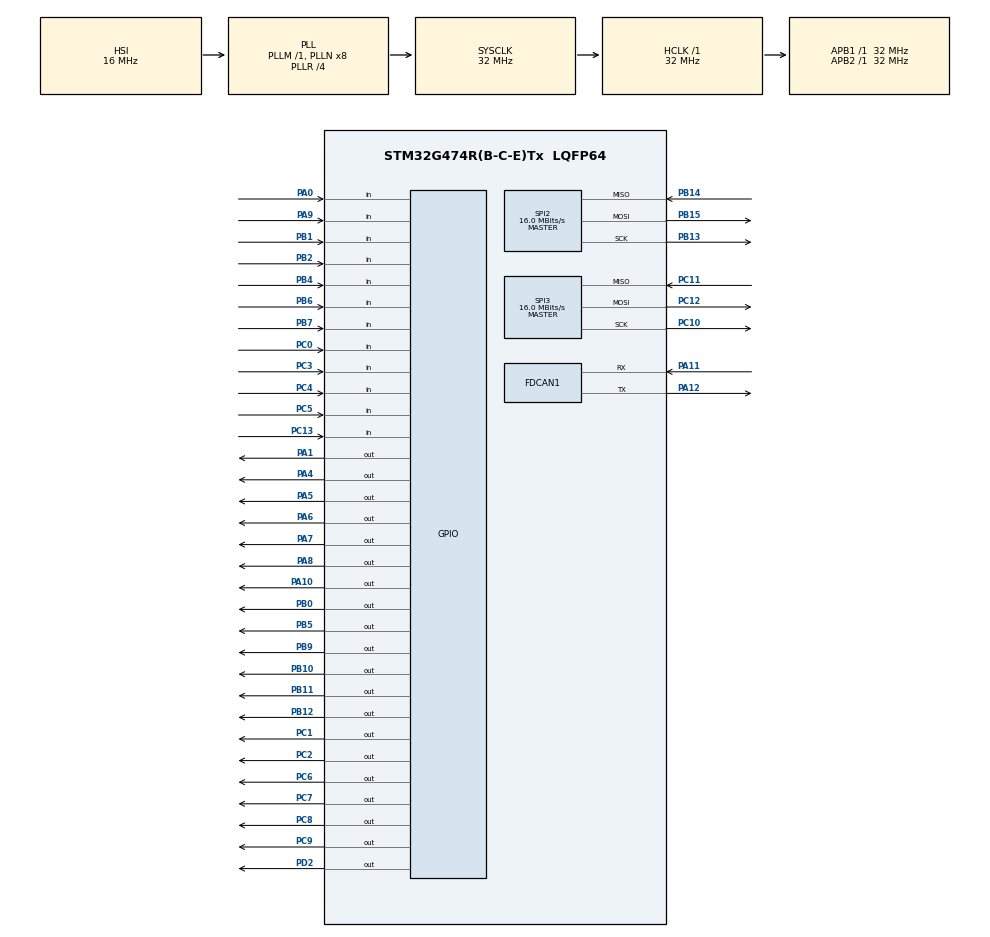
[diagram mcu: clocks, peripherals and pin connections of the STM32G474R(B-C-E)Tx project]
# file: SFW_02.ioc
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FDCAN1.CalculateBaudRateNominal=666666
FDCAN1.CalculateTimeBitNominal=1500
FDCAN1.CalculateTimeQuantumNominal=500.0
Mcu.Family=STM32G4
Mcu.Name=STM32G474R(B-C-E)Tx
Mcu.Package=LQFP64
NVIC.PriorityGroup=NVIC_PRIORITYGROUP_4
NVIC.TIM2_IRQn=true\:0\:0\:false\:false\:true\:true\:true\:true
PA0.Signal=GPIO_Input
PA1.Signal=GPIO_Output
PA10.Signal=GPIO_Output
PA11.Mode=FDCAN_Activate
PA11.Signal=FDCAN1_RX
PA12.Mode=FDCAN_Activate
PA12.Signal=FDCAN1_TX
PA13.Signal=SYS_JTMS-SWDIO
PA14.Signal=SYS_JTCK-SWCLK
PA15.Signal=SYS_JTDI
PA2.Signal=LPUART1_TX
PA3.Signal=LPUART1_RX
PA4.Signal=GPIO_Output
PA5.Signal=GPIO_Output
PA6.Signal=GPIO_Output
PA7.Signal=GPIO_Output
PA8.Signal=GPIO_Output
PA9.Signal=GPIO_Input
PB0.Signal=GPIO_Output
PB1.Signal=GPIO_Input
PB10.Signal=GPIO_Output
PB11.Signal=GPIO_Output
PB12.Signal=GPIO_Output
PB13.Mode=Full_Duplex_Master
PB13.Signal=SPI2_SCK
PB14.Mode=Full_Duplex_Master
PB14.Signal=SPI2_MISO
PB15.Mode=Full_Duplex_Master
PB15.Signal=SPI2_MOSI
PB2.Signal=GPIO_Input
PB3.Signal=SYS_JTDO-SWO
PB4.Signal=GPIO_Input
PB5.Signal=GPIO_Output
PB6.Signal=GPIO_Input
PB7.Signal=GPIO_Input
PB9.Signal=GPIO_Output
PC0.Signal=GPIO_Input
PC1.Signal=GPIO_Output
PC10.Mode=Full_Duplex_Master
PC10.Signal=SPI3_SCK
PC11.Mode=Full_Duplex_Master
PC11.Signal=SPI3_MISO
PC12.Mode=Full_Duplex_Master
PC12.Signal=SPI3_MOSI
PC13.Signal=GPIO_Input
PC14-OSC32_IN.Mode=LSE-External-Oscillator
PC14-OSC32_IN.Signal=RCC_OSC32_IN
PC15-OSC32_OUT.Mode=LSE-External-Oscillator
PC15-OSC32_OUT.Signal=RCC_OSC32_OUT
PC2.Signal=GPIO_Output
PC3.Signal=GPIO_Input
PC4.Signal=GPIO_Input
PC5.Signal=GPIO_Input
PC6.Signal=GPIO_Output
PC7.Signal=GPIO_Output
PC8.Signal=GPIO_Output
PC9.Signal=GPIO_Output
PD2.Signal=GPIO_Output
PF0-OSC_IN.Mode=HSE-External-Oscillator
PF0-OSC_IN.Signal=RCC_OSC_IN
PF1-OSC_OUT.Mode=HSE-External-Oscillator
PF1-OSC_OUT.Signal=RCC_OSC_OUT
ProjectManager.HeapSize=0x200
ProjectManager.StackSize=0x400
ProjectManager.TargetToolchain=STM32CubeIDE
RCC.ADC12Freq_Value=32000000
RCC.ADC345Freq_Value=32000000
RCC.AHBFreq_Value=32000000
RCC.APB1Freq_Value=32000000
RCC.APB1TimFreq_Value=32000000
RCC.APB2Freq_Value=32000000
RCC.APB2TimFreq_Value=32000000
RCC.CortexFreq_Value=32000000
RCC.EXTERNAL_CLOCK_VALUE=12288000
RCC.HCLKFreq_Value=32000000
RCC.HSE_VALUE=24000000
RCC.HSI48_VALUE=48000000
RCC.HSI_VALUE=16000000
RCC.PLLR=RCC_PLLR_DIV4
RCC.SYSCLKFreq_VALUE=32000000
RCC.SYSCLKSource=RCC_SYSCLKSOURCE_PLLCLK
RCC.USBFreq_Value=64000000
RCC.VCOOutputFreq_Value=128000000
SPI2.BaudRatePrescaler=SPI_BAUDRATEPRESCALER_2
SPI2.CalculateBaudRate=16.0 MBits/s
SPI2.Direction=SPI_DIRECTION_2LINES
SPI2.Mode=SPI_MODE_MASTER
SPI2.VirtualType=VM_MASTER
SPI3.BaudRatePrescaler=SPI_BAUDRATEPRESCALER_2
SPI3.CalculateBaudRate=16.0 MBits/s
SPI3.Direction=SPI_DIRECTION_2LINES
SPI3.Mode=SPI_MODE_MASTER
SPI3.VirtualType=VM_MASTER
TIM2.Channel-PWM\ Generation1\ No\ Output=TIM_CHANNEL_1
TIM2.PeriodNoDither=999
TIM2.Prescaler=320
VP_SYS_VS_DBSignals.Mode=DisableDeadBatterySignals
VP_TIM2_VS_ClockSourceINT.Mode=Internal
VP_TIM2_VS_no_output1.Mode=PWM Generation1 No Output
VREF+.Mode=InternalMode
VREF+.Signal=VREFBUF_OUT
board=custom

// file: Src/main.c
/* USER CODE BEGIN Header */
/**
  ******************************************************************************
  * @file           : main.c
  * @brief          : Main program body
  ******************************************************************************
  * @attention
  *
  * Copyright (c) 2026 STMicroelectronics.
  * All rights reserved.
  *
  * This software is licensed under terms that can be found in the LICENSE file
  * in the root directory of this software component.
  * If no LICENSE file comes with this software, it is provided AS-IS.
  *
  ******************************************************************************
  */
/* USER CODE END Header */
#include "main.h"

/* USER CODE BEGIN Includes */
#include "stm32g4xx_hal.h"
#include "vnf1248.h"
/* USER CODE END Includes */

FDCAN_HandleTypeDef hfdcan1;

SPI_HandleTypeDef hspi2;
SPI_HandleTypeDef hspi3;

TIM_HandleTypeDef htim2;

/* USER CODE BEGIN PV */
uint8_t SPI2_TxBuf[4];
uint8_t SPI2_RxBuf[4];
uint8_t NVMread[3];

uint32_t k=0;
uint8_t NVMerr=0;
uint32_t cfg_word = 0;
int8_t OutputState=0;
/* USER CODE END PV */

void SystemClock_Config(void);
static void MX_GPIO_Init(void);
static void MX_FDCAN1_Init(void);
static void MX_SPI2_Init(void);
static void MX_SPI3_Init(void);
static void MX_TIM2_Init(void);

int main(void)
{

  /* MCU Configuration--------------------------------------------------------*/

  /* Reset of all peripherals, Initializes the Flash interface and the Systick. */
  HAL_Init();

  /* Configure the system clock */
  SystemClock_Config();

  /* Initialize all configured peripherals */
  MX_GPIO_Init();
  MX_FDCAN1_Init();
  MX_SPI2_Init();
  MX_SPI3_Init();
  MX_TIM2_Init();
//  HAL_TIM_Base_Start_IT(&htim2);
  /* USER CODE BEGIN 2 */

  //Initialize_vnf(&hspi2, GPIOC, GPIO_PIN_1);
  Initialize_vnf(&hspi2, GPIOC, GPIO_PIN_2);  // ch. B

  //NVMerr = RW_NVM_vnf(&hspi2, GPIOC, GPIO_PIN_2, 1);  // read NVM
  //RW_NVM_vnf(&hspi2, GPIOC, GPIO_PIN_2, 0);  // write NVM

  HAL_TIM_Base_Start_IT(&htim2);  // the interrupts is used to service VNF WD

  /* USER CODE END 2 */

  /* Infinite loop */
  /* USER CODE BEGIN WHILE */
  while (1)
  {
	  HAL_GPIO_TogglePin(GPIOB, GPIO_PIN_11);

	  if(HAL_GPIO_ReadPin(GPIOC, GPIO_PIN_3)==GPIO_PIN_SET)	// poll user button ; =0 when pressed
	  {
      HAL_GPIO_WritePin(GPIOB, GPIO_PIN_9, GPIO_PIN_RESET);	// disable 5V supply

	  }
	  else // button pressed
	  {

      // Read CR1
      SPI2_TxBuf[0] = 0b01000000|CR1_ADDR; // 0b01 = read command
      SPI2_TxBuf[1] = 0b00000000;
      SPI2_TxBuf[2] = 0b00000000;
      SPI2_TxBuf[3] = 0b00000000;
      VNF_TransmitReceive(&hspi2, GPIOC, GPIO_PIN_2, SPI2_TxBuf, SPI2_RxBuf);

      // CURRENT SENSE SELF-TEST
      // Read CR1
      SPI2_TxBuf[0] = 0b01000000|CR1_ADDR; // 0b01 = read command
      SPI2_TxBuf[1] = 0b00000000;
      SPI2_TxBuf[2] = 0b00000000;
      SPI2_TxBuf[3] = 0b00000000;
      VNF_TransmitReceive(&hspi2, GPIOC, GPIO_PIN_2, SPI2_TxBuf, SPI2_RxBuf);

      // Flip relevant bits and write CR1
      SPI2_TxBuf[0] = CR1_ADDR; // 0b00 = write command
      SPI2_TxBuf[1] = SPI2_RxBuf[1];
      SPI2_TxBuf[2] = SPI2_RxBuf[2]|0b10; // S_T_START bit = 1
      SPI2_TxBuf[3] = (SPI2_RxBuf[3]&0x1F)|0x20; // self-test current sense
      VNF_TransmitReceive(&hspi2, GPIOC, GPIO_PIN_2, SPI2_TxBuf, SPI2_RxBuf);

      // Read SR7
      SPI2_TxBuf[0] = 0b01000000|SR7_ADDR; // 0b01 = read command
      SPI2_TxBuf[1] = 0b00000000;
      SPI2_TxBuf[2] = 0b00000000;
      SPI2_TxBuf[3] = 0b00000000;
      VNF_TransmitReceive(&hspi2, GPIOC, GPIO_PIN_2, SPI2_TxBuf, SPI2_RxBuf);

      /*
      // FET STUCK ON SELF-TEST
      // Read CR1
      SPI2_TxBuf[0] = 0b01000000|CR1_ADDR; // 0b01 = read command
      SPI2_TxBuf[1] = 0b00000000;
      SPI2_TxBuf[2] = 0b00000000;
      SPI2_TxBuf[3] = 0b00000000;
      VNF_TransmitReceive(&hspi2, GPIOC, GPIO_PIN_2, SPI2_TxBuf, SPI2_RxBuf);

      // Flip relevant bits and write CR1
      SPI2_TxBuf[0] = CR1_ADDR; // 0b00 = write command
      SPI2_TxBuf[1] = SPI2_RxBuf[1];
      SPI2_TxBuf[2] = SPI2_RxBuf[2]|0b10; // S_T_START bit = 1
      SPI2_TxBuf[3] = (SPI2_RxBuf[3]&0x1F)|0x80; // self-test fet stuck-on
      VNF_TransmitReceive(&hspi2, GPIOC, GPIO_PIN_2, SPI2_TxBuf, SPI2_RxBuf);

      // Read SR6
      SPI2_TxBuf[0] = 0b01000000|SR6_ADDR; // 0b01 = read command
      SPI2_TxBuf[1] = 0b00000000;
      SPI2_TxBuf[2] = 0b00000000;
      SPI2_TxBuf[3] = 0b00000000;
      VNF_TransmitReceive(&hspi2, GPIOC, GPIO_PIN_2, SPI2_TxBuf, SPI2_RxBuf);
      */

      // PRE-CHARGE, TURN ON, THEN RUN VDS SELF-CHECK
      if(OutputState==0)
      {
        OutputState = 1; // using 1 for CCM
        //HAL_GPIO_WritePin(GPIOB, GPIO_PIN_10, GPIO_PIN_SET);

        // use pre-charge current trip threshold
        SPI2_TxBuf[0] = CR2_ADDR;
        SPI2_TxBuf[1] = (CR2_PRCHG&0x00FF0000)>>16;
		    SPI2_TxBuf[2] = (CR2_PRCHG&0x0000FF00)>>8;
		    SPI2_TxBuf[3] = (CR2_PRCHG&0x000000FF);
		    VNF_TransmitReceive(&hspi2, GPIOC, GPIO_PIN_2, SPI2_TxBuf, SPI2_RxBuf);

        SPI2_TxBuf[0] = CR1_ADDR; //0x008400
        SPI2_TxBuf[1] = 0x04; // --> trigger CCM ON
        SPI2_TxBuf[2] = 0x84;
        SPI2_TxBuf[3] = 0x00;
        VNF_TransmitReceive(&hspi2, GPIOC, GPIO_PIN_2, SPI2_TxBuf, SPI2_RxBuf);

        while(OutputState == 1)
        {
          // read SR1
          SPI2_TxBuf[0] = 0b01000000|SR1_ADDR; // 0b01 = read command
          SPI2_TxBuf[1] = 0b00000000;
          SPI2_TxBuf[2] = 0b00000000;
          SPI2_TxBuf[3] = 0b00000000;
          VNF_TransmitReceive(&hspi2, GPIOC, GPIO_PIN_2, SPI2_TxBuf, SPI2_RxBuf);

          switch((SPI2_RxBuf[1]&0xC0)>>6)
          {
            case 0b10:
              OutputState=2;
              break;

            case 0b11:
              OutputState=-1;
              break;

            case 0b00:
              OutputState=-2;
              break;

            default:
              break;
          }
        }

        if (OutputState == 2)
        {
          // revert to regular current trip threshold
          SPI2_TxBuf[0] = CR2_ADDR;
          SPI2_TxBuf[1] = (CR2_CONFIG&0x00FF0000)>>16;
          SPI2_TxBuf[2] = (CR2_CONFIG&0x0000FF00)>>8;
          SPI2_TxBuf[3] = (CR2_CONFIG&0x000000FF);
          VNF_TransmitReceive(&hspi2, GPIOC, GPIO_PIN_2, SPI2_TxBuf, SPI2_RxBuf);

          // turn FET ON
          SPI2_TxBuf[0] = CR1_ADDR; //0x008400
          SPI2_TxBuf[1] = 0x00;
          SPI2_TxBuf[2] = 0x84;
          SPI2_TxBuf[3] = 0x11; //--> turn on main FET
          VNF_TransmitReceive(&hspi2, GPIOC, GPIO_PIN_2, SPI2_TxBuf, SPI2_RxBuf);
          //HAL_GPIO_WritePin(GPIOB, GPIO_PIN_10, GPIO_PIN_RESET);

          // might need a delay here (to let motor current stabilize)
          // Run Vds self-check
          SPI2_TxBuf[0] = 0b01000000|CR1_ADDR; // 0b01 = read command
          SPI2_TxBuf[1] = 0b00000000;
          SPI2_TxBuf[2] = 0b00000000;
          SPI2_TxBuf[3] = 0b00000000;
          VNF_TransmitReceive(&hspi2, GPIOC, GPIO_PIN_2, SPI2_TxBuf, SPI2_RxBuf);

          // Flip relevant bits and write CR1
          SPI2_TxBuf[0] = CR1_ADDR; // 0b00 = write command
          SPI2_TxBuf[1] = SPI2_RxBuf[1];
          SPI2_TxBuf[2] = SPI2_RxBuf[2]|0b10; // S_T_START bit = 1
          SPI2_TxBuf[3] = (SPI2_RxBuf[3]&0x1F)|0x40; // self-test fet stuck-on
          VNF_TransmitReceive(&hspi2, GPIOC, GPIO_PIN_2, SPI2_TxBuf, SPI2_RxBuf);

          // Read SR5
          SPI2_TxBuf[0] = 0b01000000|SR5_ADDR; // 0b01 = read command
          SPI2_TxBuf[1] = 0b00000000;
          SPI2_TxBuf[2] = 0b00000000;
          SPI2_TxBuf[3] = 0b00000000;
          VNF_TransmitReceive(&hspi2, GPIOC, GPIO_PIN_2, SPI2_TxBuf, SPI2_RxBuf);
        }

      }

      // Read CR1
      SPI2_TxBuf[0] = 0b01000000|CR1_ADDR; // 0b01 = read command
      SPI2_TxBuf[1] = 0b00000000;
      SPI2_TxBuf[2] = 0b00000000;
      SPI2_TxBuf[3] = 0b00000000;
      VNF_TransmitReceive(&hspi2, GPIOC, GPIO_PIN_2, SPI2_TxBuf, SPI2_RxBuf);

      HAL_GPIO_WritePin(GPIOB, GPIO_PIN_9, GPIO_PIN_SET);	// enable 5V supply
	  }
  }
  /* USER CODE END 3 */
}

void HAL_TIM_PeriodElapsedCallback(TIM_HandleTypeDef* htim)
{
    PetWD_vnf(&hspi2, GPIOC, GPIO_PIN_2); // Ch. B
}

void SystemClock_Config(void)
{
  RCC_OscInitTypeDef RCC_OscInitStruct = {0};
  RCC_ClkInitTypeDef RCC_ClkInitStruct = {0};

  /** Configure the main internal regulator output voltage
  */
  HAL_PWREx_ControlVoltageScaling(PWR_REGULATOR_VOLTAGE_SCALE1);

  /** Initializes the RCC Oscillators according to the specified parameters
  * in the RCC_OscInitTypeDef structure.
  */
  RCC_OscInitStruct.OscillatorType = RCC_OSCILLATORTYPE_HSI;
  RCC_OscInitStruct.HSIState = RCC_HSI_ON;
  RCC_OscInitStruct.HSICalibrationValue = RCC_HSICALIBRATION_DEFAULT;
  RCC_OscInitStruct.PLL.PLLState = RCC_PLL_ON;
  RCC_OscInitStruct.PLL.PLLSource = RCC_PLLSOURCE_HSI;
  RCC_OscInitStruct.PLL.PLLM = RCC_PLLM_DIV1;
  RCC_OscInitStruct.PLL.PLLN = 8;
  RCC_OscInitStruct.PLL.PLLP = RCC_PLLP_DIV2;
  RCC_OscInitStruct.PLL.PLLQ = RCC_PLLQ_DIV2;
  RCC_OscInitStruct.PLL.PLLR = RCC_PLLR_DIV4;
  if (HAL_RCC_OscConfig(&RCC_OscInitStruct) != HAL_OK)
  {
    Error_Handler();
  }

  /** Initializes the CPU, AHB and APB buses clocks
  */
  RCC_ClkInitStruct.ClockType = RCC_CLOCKTYPE_HCLK|RCC_CLOCKTYPE_SYSCLK
                              |RCC_CLOCKTYPE_PCLK1|RCC_CLOCKTYPE_PCLK2;
  RCC_ClkInitStruct.SYSCLKSource = RCC_SYSCLKSOURCE_PLLCLK;
  RCC_ClkInitStruct.AHBCLKDivider = RCC_SYSCLK_DIV1;
  RCC_ClkInitStruct.APB1CLKDivider = RCC_HCLK_DIV1;
  RCC_ClkInitStruct.APB2CLKDivider = RCC_HCLK_DIV1;

  if (HAL_RCC_ClockConfig(&RCC_ClkInitStruct, FLASH_LATENCY_1) != HAL_OK)
  {
    Error_Handler();
  }
}

static void MX_FDCAN1_Init(void)
{

  hfdcan1.Instance = FDCAN1;
  hfdcan1.Init.ClockDivider = FDCAN_CLOCK_DIV1;
  hfdcan1.Init.FrameFormat = FDCAN_FRAME_CLASSIC;
  hfdcan1.Init.Mode = FDCAN_MODE_NORMAL;
  hfdcan1.Init.AutoRetransmission = DISABLE;
  hfdcan1.Init.TransmitPause = DISABLE;
  hfdcan1.Init.ProtocolException = DISABLE;
  hfdcan1.Init.NominalPrescaler = 16;
  hfdcan1.Init.NominalSyncJumpWidth = 1;
  hfdcan1.Init.NominalTimeSeg1 = 1;
  hfdcan1.Init.NominalTimeSeg2 = 1;
  hfdcan1.Init.DataPrescaler = 1;
  hfdcan1.Init.DataSyncJumpWidth = 1;
  hfdcan1.Init.DataTimeSeg1 = 1;
  hfdcan1.Init.DataTimeSeg2 = 1;
  hfdcan1.Init.StdFiltersNbr = 0;
  hfdcan1.Init.ExtFiltersNbr = 0;
  hfdcan1.Init.TxFifoQueueMode = FDCAN_TX_FIFO_OPERATION;
  if (HAL_FDCAN_Init(&hfdcan1) != HAL_OK)
  {
    Error_Handler();
  }

}

static void MX_SPI2_Init(void)
{

  /* SPI2 parameter configuration*/
  hspi2.Instance = SPI2;
  hspi2.Init.Mode = SPI_MODE_MASTER;
  hspi2.Init.Direction = SPI_DIRECTION_2LINES;
  hspi2.Init.DataSize = SPI_DATASIZE_8BIT;
  hspi2.Init.CLKPolarity = SPI_POLARITY_LOW;
  hspi2.Init.CLKPhase = SPI_PHASE_1EDGE;
  hspi2.Init.NSS = SPI_NSS_SOFT;
  hspi2.Init.BaudRatePrescaler = SPI_BAUDRATEPRESCALER_4;
  hspi2.Init.FirstBit = SPI_FIRSTBIT_MSB;
  hspi2.Init.TIMode = SPI_TIMODE_DISABLE;
  hspi2.Init.CRCCalculation = SPI_CRCCALCULATION_DISABLE;
  hspi2.Init.CRCPolynomial = 7;
  hspi2.Init.CRCLength = SPI_CRC_LENGTH_DATASIZE;
  hspi2.Init.NSSPMode = SPI_NSS_PULSE_ENABLE;
  if (HAL_SPI_Init(&hspi2) != HAL_OK)
  {
    Error_Handler();
  }

}

static void MX_SPI3_Init(void)
{

  /* SPI3 parameter configuration*/
  hspi3.Instance = SPI3;
  hspi3.Init.Mode = SPI_MODE_MASTER;
  hspi3.Init.Direction = SPI_DIRECTION_2LINES;
  hspi3.Init.DataSize = SPI_DATASIZE_4BIT;
  hspi3.Init.CLKPolarity = SPI_POLARITY_LOW;
  hspi3.Init.CLKPhase = SPI_PHASE_1EDGE;
  hspi3.Init.NSS = SPI_NSS_SOFT;
  hspi3.Init.BaudRatePrescaler = SPI_BAUDRATEPRESCALER_2;
  hspi3.Init.FirstBit = SPI_FIRSTBIT_MSB;
  hspi3.Init.TIMode = SPI_TIMODE_DISABLE;
  hspi3.Init.CRCCalculation = SPI_CRCCALCULATION_DISABLE;
  hspi3.Init.CRCPolynomial = 7;
  hspi3.Init.CRCLength = SPI_CRC_LENGTH_DATASIZE;
  hspi3.Init.NSSPMode = SPI_NSS_PULSE_ENABLE;
  if (HAL_SPI_Init(&hspi3) != HAL_OK)
  {
    Error_Handler();
  }

}

static void MX_TIM2_Init(void)
{

  TIM_ClockConfigTypeDef sClockSourceConfig = {0};
  TIM_MasterConfigTypeDef sMasterConfig = {0};
  TIM_OC_InitTypeDef sConfigOC = {0};

  htim2.Instance = TIM2;
  htim2.Init.Prescaler = 319;
  htim2.Init.CounterMode = TIM_COUNTERMODE_UP;
  htim2.Init.Period = 9999;
  htim2.Init.ClockDivision = TIM_CLOCKDIVISION_DIV1;
  htim2.Init.AutoReloadPreload = TIM_AUTORELOAD_PRELOAD_DISABLE;
  if (HAL_TIM_Base_Init(&htim2) != HAL_OK)
  {
    Error_Handler();
  }
  sClockSourceConfig.ClockSource = TIM_CLOCKSOURCE_INTERNAL;
  if (HAL_TIM_ConfigClockSource(&htim2, &sClockSourceConfig) != HAL_OK)
  {
    Error_Handler();
  }
  if (HAL_TIM_PWM_Init(&htim2) != HAL_OK)
  {
    Error_Handler();
  }
  sMasterConfig.MasterOutputTrigger = TIM_TRGO_RESET;
  sMasterConfig.MasterSlaveMode = TIM_MASTERSLAVEMODE_DISABLE;
  if (HAL_TIMEx_MasterConfigSynchronization(&htim2, &sMasterConfig) != HAL_OK)
  {
    Error_Handler();
  }
  sConfigOC.OCMode = TIM_OCMODE_PWM1;
  sConfigOC.Pulse = 0;
  sConfigOC.OCPolarity = TIM_OCPOLARITY_HIGH;
  sConfigOC.OCFastMode = TIM_OCFAST_DISABLE;
  if (HAL_TIM_PWM_ConfigChannel(&htim2, &sConfigOC, TIM_CHANNEL_1) != HAL_OK)
  {
    Error_Handler();
  }

}

static void MX_GPIO_Init(void)
{
  GPIO_InitTypeDef GPIO_InitStruct = {0};

  /* GPIO Ports Clock Enable */
  __HAL_RCC_GPIOC_CLK_ENABLE();
  __HAL_RCC_GPIOF_CLK_ENABLE();
  __HAL_RCC_GPIOA_CLK_ENABLE();
  __HAL_RCC_GPIOB_CLK_ENABLE();
  __HAL_RCC_GPIOD_CLK_ENABLE();

  /*Configure GPIO pin Output Level */
  HAL_GPIO_WritePin(GPIOC, GPIO_PIN_1|GPIO_PIN_2|GPIO_PIN_6|GPIO_PIN_7
                          |GPIO_PIN_8|GPIO_PIN_9, GPIO_PIN_RESET);

  /*Configure GPIO pin Output Level */
  HAL_GPIO_WritePin(GPIOA, GPIO_PIN_1|GPIO_PIN_4|GPIO_PIN_5|GPIO_PIN_6
                          |GPIO_PIN_7|GPIO_PIN_8|GPIO_PIN_10, GPIO_PIN_RESET);

  /*Configure GPIO pin Output Level */
  HAL_GPIO_WritePin(GPIOB, GPIO_PIN_0|GPIO_PIN_10|GPIO_PIN_11|GPIO_PIN_12
                          |GPIO_PIN_5|GPIO_PIN_9, GPIO_PIN_RESET);

  /*Configure GPIO pin Output Level */
  HAL_GPIO_WritePin(GPIOD, GPIO_PIN_2, GPIO_PIN_RESET);

  /*Configure GPIO pins : PC13 PC0 PC3 PC4
                           PC5 */
  GPIO_InitStruct.Pin = GPIO_PIN_13|GPIO_PIN_0|GPIO_PIN_3|GPIO_PIN_4
                          |GPIO_PIN_5;
  GPIO_InitStruct.Mode = GPIO_MODE_INPUT;
  GPIO_InitStruct.Pull = GPIO_NOPULL;
  HAL_GPIO_Init(GPIOC, &GPIO_InitStruct);

  /*Configure GPIO pins : PC1 PC2 PC6 PC7
                           PC8 PC9 */
  GPIO_InitStruct.Pin = GPIO_PIN_1|GPIO_PIN_2|GPIO_PIN_6|GPIO_PIN_7
                          |GPIO_PIN_8|GPIO_PIN_9;
  GPIO_InitStruct.Mode = GPIO_MODE_OUTPUT_PP;
  GPIO_InitStruct.Pull = GPIO_NOPULL;
  GPIO_InitStruct.Speed = GPIO_SPEED_FREQ_LOW;
  HAL_GPIO_Init(GPIOC, &GPIO_InitStruct);

  /*Configure GPIO pins : PA0 PA9 */
  GPIO_InitStruct.Pin = GPIO_PIN_0|GPIO_PIN_9;
  GPIO_InitStruct.Mode = GPIO_MODE_INPUT;
  GPIO_InitStruct.Pull = GPIO_NOPULL;
  HAL_GPIO_Init(GPIOA, &GPIO_InitStruct);

  /*Configure GPIO pins : PA1 PA4 PA5 PA6
                           PA7 PA8 PA10 */
  GPIO_InitStruct.Pin = GPIO_PIN_1|GPIO_PIN_4|GPIO_PIN_5|GPIO_PIN_6
                          |GPIO_PIN_7|GPIO_PIN_8|GPIO_PIN_10;
  GPIO_InitStruct.Mode = GPIO_MODE_OUTPUT_PP;
  GPIO_InitStruct.Pull = GPIO_NOPULL;
  GPIO_InitStruct.Speed = GPIO_SPEED_FREQ_LOW;
  HAL_GPIO_Init(GPIOA, &GPIO_InitStruct);

  /*Configure GPIO pins : PA2 PA3 */
  GPIO_InitStruct.Pin = GPIO_PIN_2|GPIO_PIN_3;
  GPIO_InitStruct.Mode = GPIO_MODE_AF_PP;
  GPIO_InitStruct.Pull = GPIO_NOPULL;
  GPIO_InitStruct.Speed = GPIO_SPEED_FREQ_LOW;
  GPIO_InitStruct.Alternate = GPIO_AF12_LPUART1;
  HAL_GPIO_Init(GPIOA, &GPIO_InitStruct);

  /*Configure GPIO pins : PB0 PB10 PB11 PB12
                           PB5 PB9 */
  GPIO_InitStruct.Pin = GPIO_PIN_0|GPIO_PIN_10|GPIO_PIN_11|GPIO_PIN_12
                          |GPIO_PIN_5|GPIO_PIN_9;
  GPIO_InitStruct.Mode = GPIO_MODE_OUTPUT_PP;
  GPIO_InitStruct.Pull = GPIO_NOPULL;
  GPIO_InitStruct.Speed = GPIO_SPEED_FREQ_LOW;
  HAL_GPIO_Init(GPIOB, &GPIO_InitStruct);

  /*Configure GPIO pins : PB1 PB2 PB4 PB6
                           PB7 */
  GPIO_InitStruct.Pin = GPIO_PIN_1|GPIO_PIN_2|GPIO_PIN_4|GPIO_PIN_6
                          |GPIO_PIN_7;
  GPIO_InitStruct.Mode = GPIO_MODE_INPUT;
  GPIO_InitStruct.Pull = GPIO_NOPULL;
  HAL_GPIO_Init(GPIOB, &GPIO_InitStruct);

  /*Configure GPIO pin : PD2 */
  GPIO_InitStruct.Pin = GPIO_PIN_2;
  GPIO_InitStruct.Mode = GPIO_MODE_OUTPUT_PP;
  GPIO_InitStruct.Pull = GPIO_NOPULL;
  GPIO_InitStruct.Speed = GPIO_SPEED_FREQ_LOW;
  HAL_GPIO_Init(GPIOD, &GPIO_InitStruct);

}

void Error_Handler(void)
{
  __disable_irq();
  while (1)
  {
  }
}
